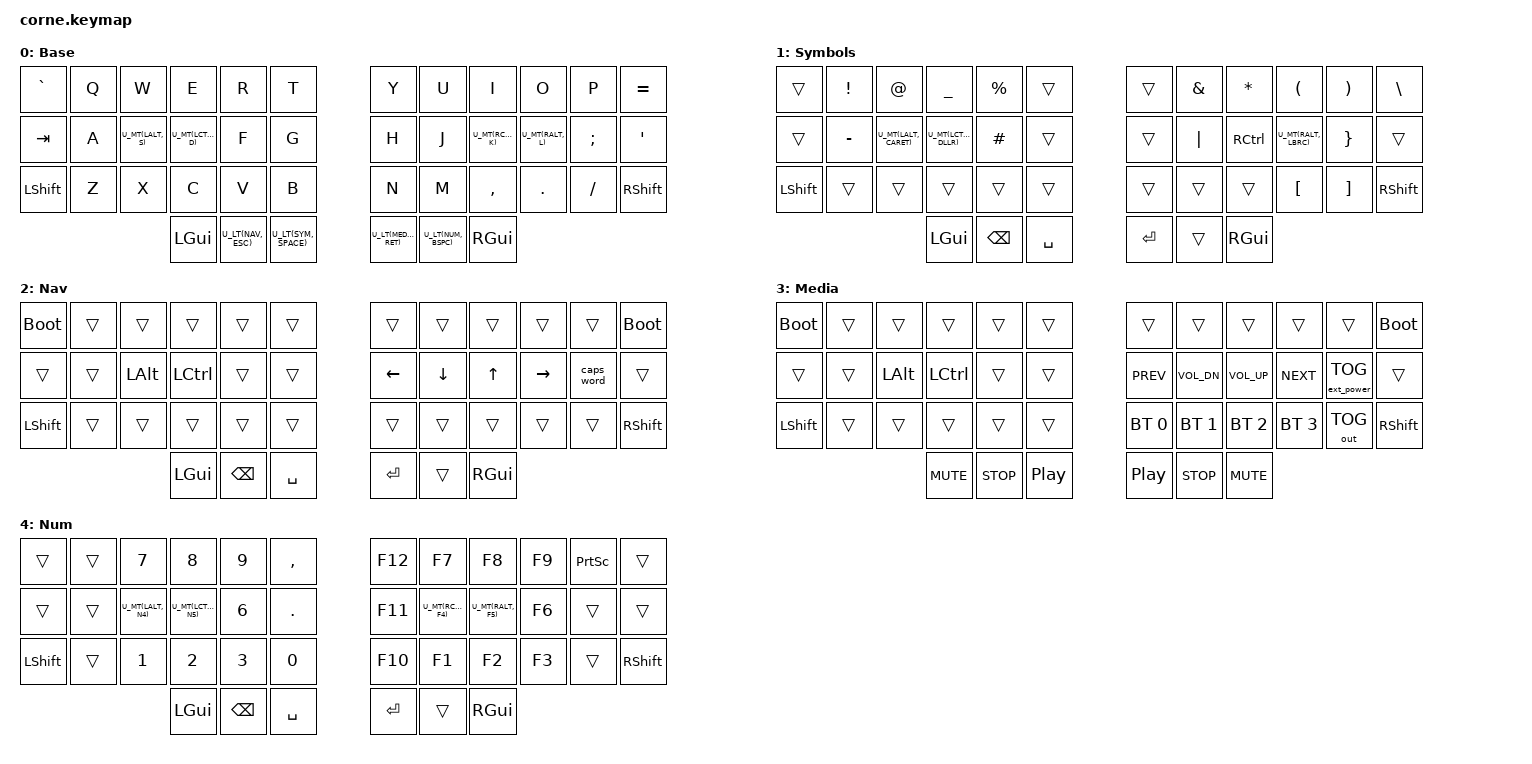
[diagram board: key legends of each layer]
/*
 * Copyright (c) 2020 The ZMK Contributors
 *
 * SPDX-License-Identifier: MIT
 */

#include <behaviors.dtsi>
#include <dt-bindings/zmk/keys.h>
#include <dt-bindings/zmk/bt.h>
#include <dt-bindings/zmk/ext_power.h>
#include <dt-bindings/zmk/outputs.h>

#define U_TAPPING_TERM 200
#define U_MT(MOD, TAP) &u_mt MOD TAP
#define U_LT(LAYER, TAP) &u_lt LAYER TAP

#define BASE 0
#define SYM 1
#define NAV 2
#define MEDIA 3
#define NUM 4


/ {
	behaviors {

	    u_mt: u_mt {
	      compatible = "zmk,behavior-hold-tap";
	      #binding-cells = <2>;
	      tapping-term-ms = <U_TAPPING_TERM>;
	      flavor = "tap-preferred";
	      bindings = <&kp>, <&kp>;
	    };

	    u_lt: u_lt {
	      compatible = "zmk,behavior-hold-tap";
	      #binding-cells = <2>;
	      tapping-term-ms = <U_TAPPING_TERM>;
	      flavor = "tap-preferred";
	      bindings = <&mo>, <&kp>;
	    };
	  };

        keymap {
                compatible = "zmk,keymap";

                base_layer {

			display-name = "Base";

                        bindings = <
   &kp GRAVE    &kp Q  &kp W          &kp E           &kp R             &kp T             &kp Y            &kp U     &kp I           &kp O          &kp P     &kp EQUAL
   &kp TAB      &kp A  U_MT(LALT, S)  U_MT(LCTRL, D)  &kp F             &kp G             &kp H            &kp J     U_MT(RCTRL, K)  U_MT(RALT, L)  &kp SEMI  &kp SQT
   &kp LSHFT    &kp Z  &kp X          &kp C           &kp V             &kp B             &kp N            &kp M     &kp COMMA       &kp DOT        &kp FSLH  &kp RSHFT
                       &kp LGUI       U_LT(NAV, ESC)  U_LT(SYM, SPACE)  U_LT(MEDIA, RET)  U_LT(NUM, BSPC)  &kp RGUI
                        >;
                };

                symbols_layer {

			display-name = "Symbols";

                        bindings = <
   &trans     &kp EXCL   &kp AT             &kp UNDER          &kp PRCNT  &trans    &trans   &kp AMPS  &kp ASTRK  &kp LPAR          &kp RPAR  &kp BSLH
   &trans     &kp MINUS  U_MT(LALT, CARET)  U_MT(LCTRL, DLLR)  &kp HASH   &trans    &trans   &kp PIPE  &kp RCTRL  U_MT(RALT, LBRC)  &kp RBRC  &trans
   &kp LSHFT  &trans     &trans             &trans             &trans     &trans    &trans   &trans    &trans     &kp LBKT          &kp RBKT  &kp RSHFT
                         &kp LGUI           &kp BSPC           &kp SPACE  &kp RET   &trans   &kp RGUI
                        >;
                };


                nav_layer {

			display-name = "Nav";

                        bindings = <
   &bootloader  &trans   &trans    &trans     &trans    &trans     &trans    &trans    &trans    &trans     &trans      &bootloader
   &trans       &trans   &kp LALT  &kp LCTRL  &trans    &trans     &kp LEFT  &kp DOWN  &kp UP    &kp RIGHT  &caps_word  &trans
   &kp LSHFT    &trans   &trans    &trans     &trans    &trans     &trans    &trans    &trans    &trans     &trans      &kp RSHFT
                                   &kp LGUI   &kp BSPC  &kp SPACE  &kp RET   &trans    &kp RGUI
                        >;
                };

                media_layer {

			display-name = "Media";

                        bindings = <

   &bootloader  &trans   &trans    &trans       &trans      &trans    &trans        &trans        &trans        &trans        &trans             &bootloader
   &trans       &trans   &kp LALT  &kp LCTRL    &trans      &trans    &kp C_PREV    &kp C_VOL_DN  &kp C_VOL_UP  &kp C_NEXT    &ext_power EP_TOG  &trans
   &kp LSHFT    &trans   &trans    &trans       &trans      &trans    &bt BT_SEL 0  &bt BT_SEL 1  &bt BT_SEL 2  &bt BT_SEL 3  &out OUT_TOG       &kp RSHFT
                                   &kp C_MUTE   &kp C_STOP  &kp C_PP  &kp C_PP      &kp C_STOP    &kp C_MUTE
                        >;
                };

		num_layer {

			display-name = "Num";

			bindings = <

   &trans     &trans   &kp N7            &kp N8           &kp N9     &kp COMMA  &kp F12  &kp F7           &kp F8          &kp F9  &kp PSCRN  &trans
   &trans     &trans   U_MT(LALT, N4)    U_MT(LCTRL, N5)  &kp N6     &kp DOT    &kp F11  U_MT(RCTRL, F4)  U_MT(RALT, F5)  &kp F6  &trans     &trans
   &kp LSHFT  &trans   &kp N1            &kp N2           &kp N3     &kp N0     &kp F10  &kp F1           &kp F2          &kp F3  &trans     &kp RSHFT
	               &kp LGUI          &kp BSPC         &kp SPACE  &kp RET    &trans   &kp RGUI
		        >;
	        };

        };
};
